# SWM181 register map
File version: 1.0
CPU: CM0 r1p0, little endian, 2 interrupt priority bits
Registers are 32-bit, read-write, no defined reset value unless marked. A register's access mark holds for its fields unless they carry their own. Offsets are from the block's base; [hi:lo] are bit positions; lines under a group give offsets from that group; {n}, {i} and the like mark numbered series.

## PORTG — Registers group
Base 0x50000000
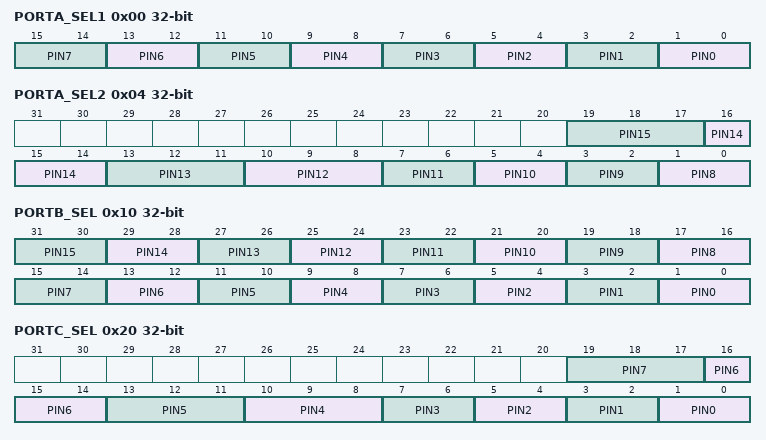
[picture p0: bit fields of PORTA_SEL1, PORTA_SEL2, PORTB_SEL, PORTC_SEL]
0x00 PORTA_SEL1
  [2n+1:2n] PIN{n} (n=0..7)
0x04 PORTA_SEL2
  [3n-26:3n-28] PIN{n} (n=12..15), [2n-15:2n-16] PIN{n} (n=8..11)
0x10 PORTB_SEL
  [2n+1:2n] PIN{n} (n=0..15)
0x20 PORTC_SEL
  [3n-2:3n-4] PIN{n} (n=4..7), [2n+1:2n] PIN{n} (n=0..3)
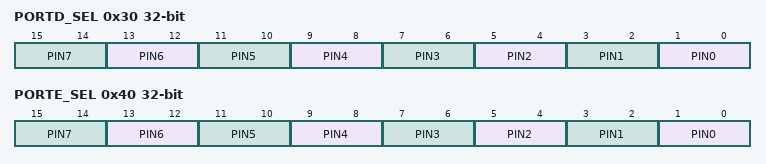
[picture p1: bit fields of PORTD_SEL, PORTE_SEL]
0x30 PORTD_SEL
  [2n+1:2n] PIN{n} (n=0..7)
0x40 PORTE_SEL
  [2n+1:2n] PIN{n} (n=0..7)

## PORTA — Registers group
Base 0x50000100
Same registers: PORTB 0x50000110, PORTC 0x50000120, PORTD 0x50000130, PORTE 0x50000140
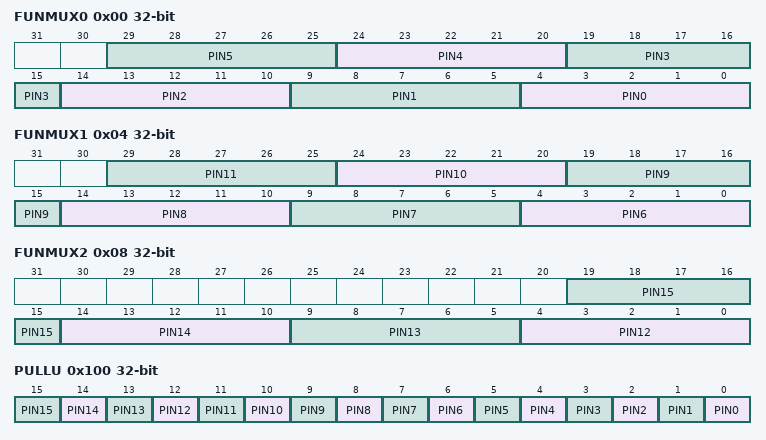
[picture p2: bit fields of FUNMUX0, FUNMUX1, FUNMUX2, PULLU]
0x00 FUNMUX0
  [5n+4:5n] PIN{n} (n=0..5)
0x04 FUNMUX1
  [5n-26:5n-30] PIN{n} (n=6..11)
0x08 FUNMUX2
  [5n-56:5n-60] PIN{n} (n=12..15)
0x100 PULLU
  [n] PIN{n} (n=0..15)
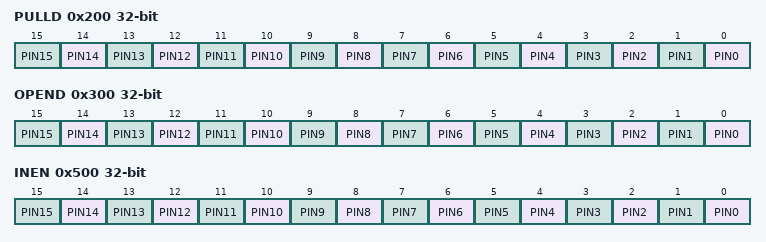
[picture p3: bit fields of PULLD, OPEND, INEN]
0x200 PULLD
  [n] PIN{n} (n=0..15)
0x300 OPEND
  [n] PIN{n} (n=0..15)
0x500 INEN
  [n] PIN{n} (n=0..15)

## GPIOA — Registers group
Base 0x50001000
Same registers: GPIOB 0x50002000, GPIOC 0x50003000, GPIOD 0x50004000, GPIOE 0x50005000
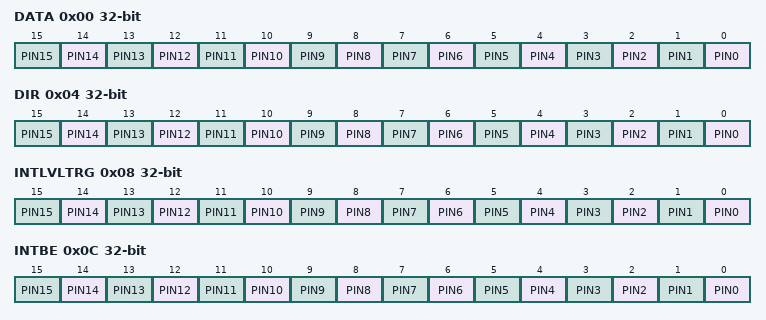
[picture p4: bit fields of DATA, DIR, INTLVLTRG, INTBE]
0x00 DATA
  [n] PIN{n} (n=0..15)
0x04 DIR
  [n] PIN{n} (n=0..15)
0x08 INTLVLTRG
  [n] PIN{n} (n=0..15)
0x0C INTBE
  [n] PIN{n} (n=0..15)
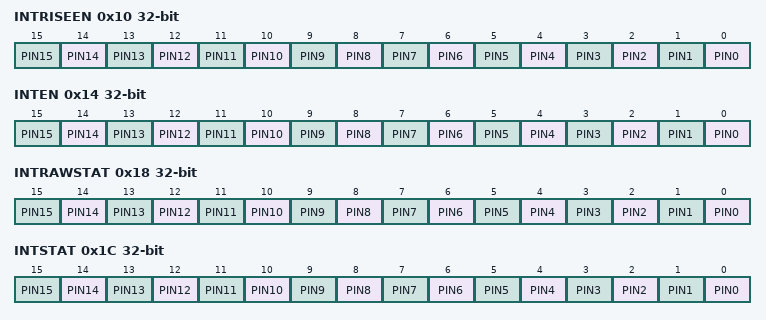
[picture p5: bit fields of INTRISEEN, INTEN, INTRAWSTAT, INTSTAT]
0x10 INTRISEEN
  [n] PIN{n} (n=0..15)
0x14 INTEN
  [n] PIN{n} (n=0..15)
0x18 INTRAWSTAT
  [n] PIN{n} (n=0..15)
0x1C INTSTAT
  [n] PIN{n} (n=0..15)
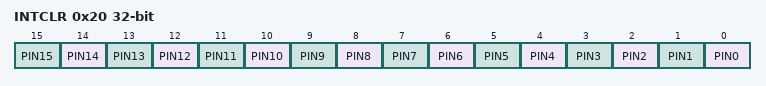
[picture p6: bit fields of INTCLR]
0x20 INTCLR
  [n] PIN{n} (n=0..15)

## TIMR0 — Registers group
Base 0x50007000
Same registers: TIMR1 0x5000700C, TIMR2 0x50007018, TIMR3 0x50007024
0x00 LDVAL
0x04 CVAL ro
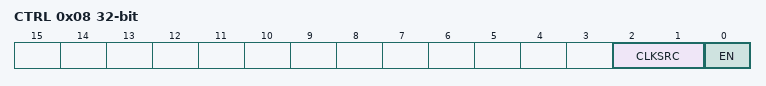
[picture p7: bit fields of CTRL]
0x08 CTRL
  [2:1] CLKSRC, [0] EN

## TIMRG — Registers group
Base 0x50007060
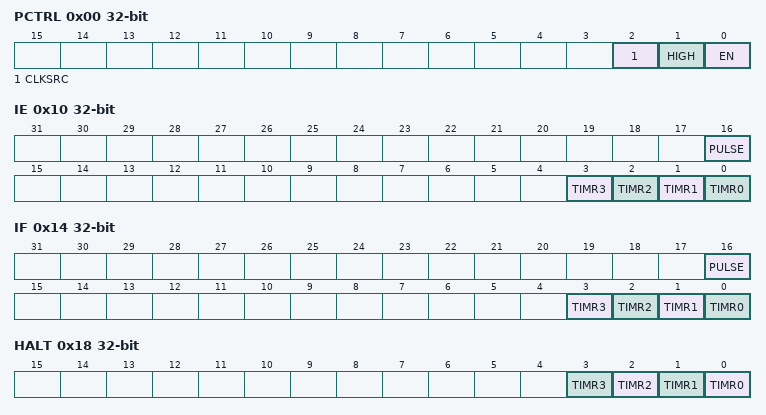
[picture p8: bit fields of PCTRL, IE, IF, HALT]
0x00 PCTRL
  [2] CLKSRC, [1] HIGH, [0] EN
0x04 PCVAL ro
0x10 IE
  [16] PULSE, [n] TIMR{n} (n=0..3)
0x14 IF
  [16] PULSE, [n] TIMR{n} (n=0..3)
0x18 HALT
  [n] TIMR{n} (n=0..3)
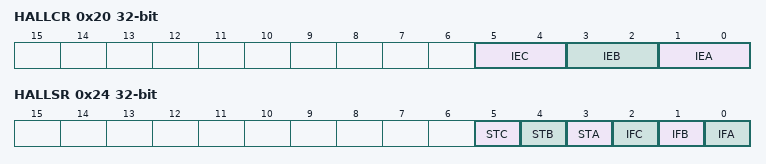
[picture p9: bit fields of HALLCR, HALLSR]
0x20 HALLCR
  [5:4] IEC, [3:2] IEB, [1:0] IEA
0x24 HALLSR
  [5] STC, [4] STB, [3] STA, [2] IFC, [1] IFB, [0] IFA
0x30 HALL_A
0x34 HALL_B
0x38 HALL_C

## UART0 — Registers group
Base 0x50010000
Same registers: UART1 0x50011000, UART2 0x50012000, UART3 0x50013000
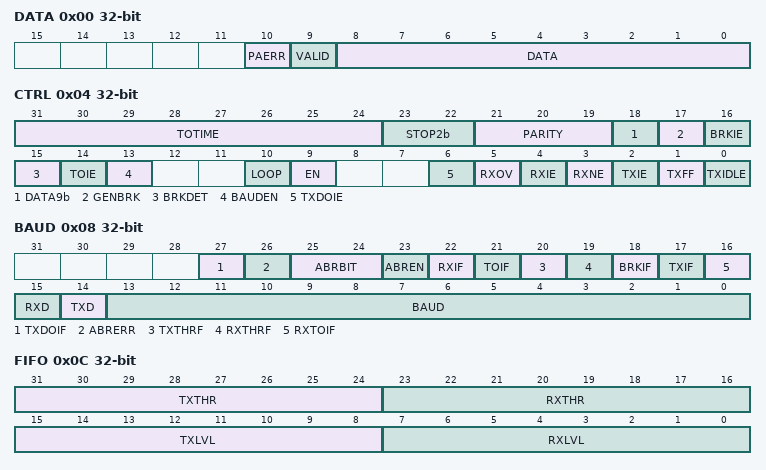
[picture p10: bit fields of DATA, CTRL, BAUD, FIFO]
0x00 DATA
  [10] PAERR, [9] VALID, [8:0] DATA
0x04 CTRL
  [31:24] TOTIME, [23:22] STOP2b, [21:19] PARITY, [18] DATA9b, [17] GENBRK, [16] BRKIE, [15] BRKDET, [14] TOIE, [13] BAUDEN, [10] LOOP, [9] EN, [6] TXDOIE, [5] RXOV, [4] RXIE, [3] RXNE, [2] TXIE, [1] TXFF, [0] TXIDLE
0x08 BAUD
  [27] TXDOIF, [26] ABRERR, [25:24] ABRBIT, [23] ABREN, [22] RXIF, [21] TOIF, [20] TXTHRF, [19] RXTHRF, [18] BRKIF, [17] TXIF, [16] RXTOIF, [15] RXD, [14] TXD, [13:0] BAUD
0x0C FIFO
  [31:24] TXTHR, [23:16] RXTHR, [15:8] TXLVL, [7:0] RXLVL
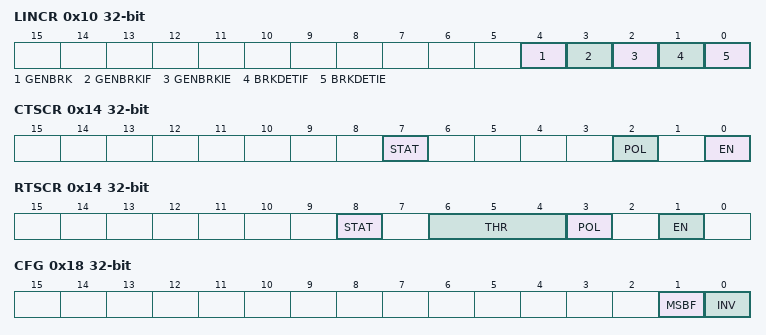
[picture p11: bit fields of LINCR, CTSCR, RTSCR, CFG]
0x10 LINCR
  [4] GENBRK, [3] GENBRKIF, [2] GENBRKIE, [1] BRKDETIF, [0] BRKDETIE
0x14 CTSCR
  [7] STAT, [2] POL, [0] EN
0x14 RTSCR (alternate view of CTSCR)
  [8] STAT, [6:4] THR, [3] POL, [1] EN
0x18 CFG
  [1] MSBF, [0] INV

## SPI0 — Registers group
Base 0x5001C000
Same registers: SPI1 0x5001D000
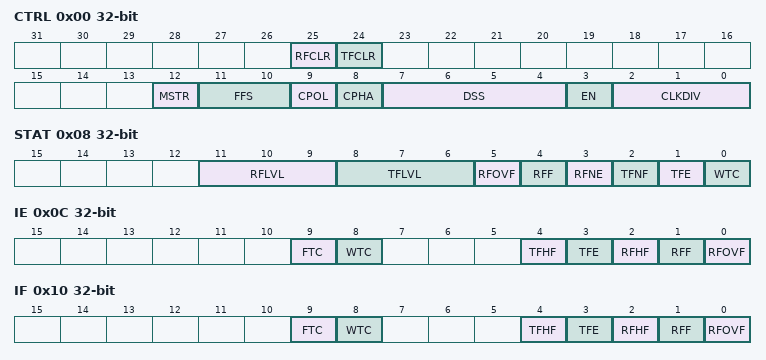
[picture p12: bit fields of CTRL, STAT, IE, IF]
0x00 CTRL
  [25] RFCLR, [24] TFCLR, [12] MSTR, [11:10] FFS, [9] CPOL, [8] CPHA, [7:4] DSS, [3] EN, [2:0] CLKDIV
0x04 DATA
0x08 STAT
  [11:9] RFLVL, [8:6] TFLVL, [5] RFOVF, [4] RFF, [3] RFNE, [2] TFNF, [1] TFE, [0] WTC
0x0C IE
  [9] FTC, [8] WTC, [4] TFHF, [3] TFE, [2] RFHF, [1] RFF, [0] RFOVF
0x10 IF
  [9] FTC, [8] WTC, [4] TFHF, [3] TFE, [2] RFHF, [1] RFF, [0] RFOVF

## I2C0 — Registers group
Base 0x50018000
Same registers: I2C1 0x50019000
0x00 CLKDIV
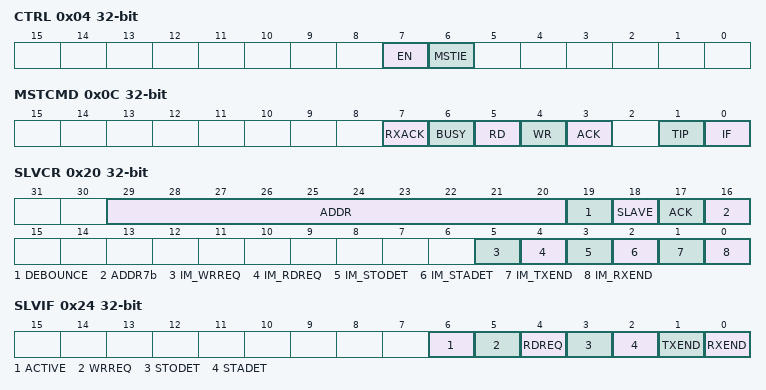
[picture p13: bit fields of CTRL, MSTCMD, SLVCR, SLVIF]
0x04 CTRL
  [7] EN, [6] MSTIE
0x08 MSTDAT
0x0C MSTCMD
  [7] RXACK, [6] BUSY, [5] RD, [4] WR, [3] ACK, [1] TIP, [0] IF
0x20 SLVCR
  [29:20] ADDR, [19] DEBOUNCE, [18] SLAVE, [17] ACK, [16] ADDR7b, [5] IM_WRREQ, [4] IM_RDREQ, [3] IM_STODET, [2] IM_STADET, [1] IM_TXEND, [0] IM_RXEND
0x24 SLVIF
  [6] ACTIVE, [5] WRREQ, [4] RDREQ, [3] STODET, [2] STADET, [1] TXEND, [0] RXEND
0x28 SLVTX
0x2C SLVRX
0x30 SLVAM
